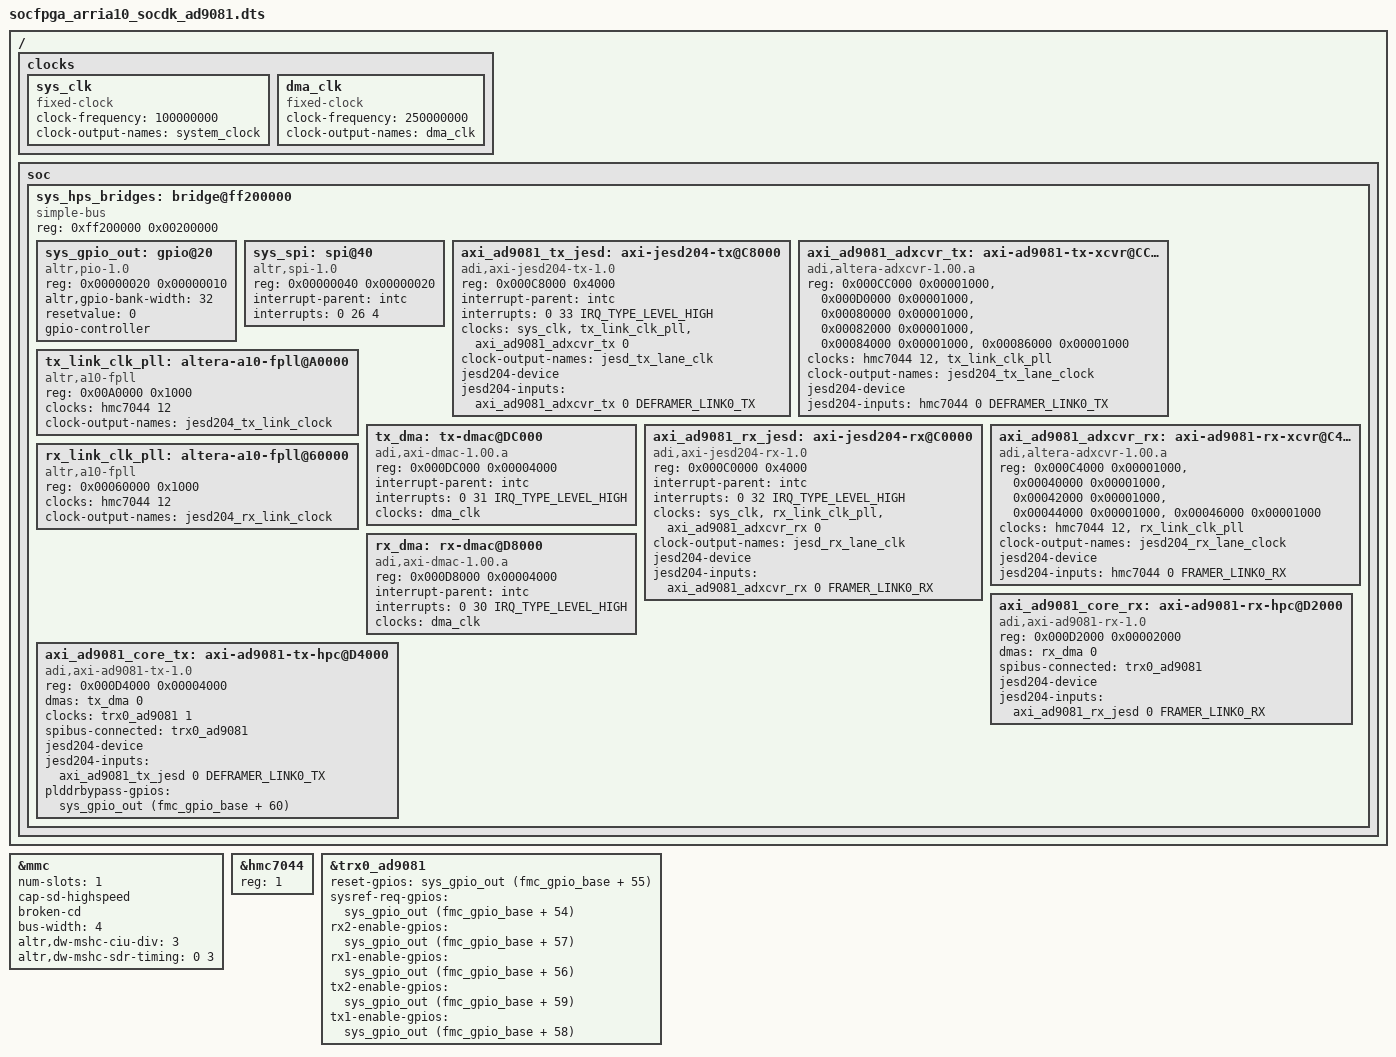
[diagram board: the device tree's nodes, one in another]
// SPDX-License-Identifier: GPL-2.0
/*
 * Analog Devices AD9081
 * https://wiki.analog.com/resources/eval/user-guides/ad9081_fmca_ebz
 * https://wiki.analog.com/resources/tools-software/linux-drivers/iio-mxfe/ad9081
 *
 * hdl_project: <ad9081_fmca_ebz/a10soc>
 * board_revision: <>
 *
 * Copyright (C) 2019 Analog Devices Inc.
 */
/dts-v1/;

#include "socfpga_arria10_socdk.dtsi"
#include <dt-bindings/interrupt-controller/irq.h>
#include <dt-bindings/iio/adc/adi,ad9081.h>
#include <dt-bindings/jesd204/adxcvr.h>

&mmc {
	status = "okay";
	num-slots = <1>;
	cap-sd-highspeed;
	broken-cd;
	bus-width = <4>;
	altr,dw-mshc-ciu-div = <3>;
	altr,dw-mshc-sdr-timing = <0 3>;
};

/ {
	clocks {
		sys_clk: sys_clk {
			#clock-cells = <0>;
			compatible = "fixed-clock";
			clock-frequency = <100000000>;
			clock-output-names = "system_clock";
		};

		dma_clk: dma_clk {
			#clock-cells = <0x0>;
			compatible = "fixed-clock";
			clock-frequency = <250000000>;
			clock-output-names = "dma_clk";
		};
	};

	soc {
		sys_hps_bridges: bridge@ff200000 {
			compatible = "simple-bus";
			reg = <0xff200000 0x00200000>;
			#address-cells = <1>;
			#size-cells = <1>;
			ranges = <0x00000000 0xff200000 0x00200000>;

			sys_gpio_out: gpio@20 {
				compatible = "altr,pio-1.0";
				reg = <0x00000020 0x00000010>;
				altr,gpio-bank-width = <32>;
				resetvalue = <0>;
				#gpio-cells = <2>;
				gpio-controller;
			};

			sys_spi: spi@40 {
				compatible = "altr,spi-1.0";
				reg = <0x00000040 0x00000020>;
				interrupt-parent = <&intc>;
				interrupts = <0 26 4>;
				#address-cells = <0x1>;
				#size-cells = <0x0>;
			};

			axi_ad9081_tx_jesd: axi-jesd204-tx@C8000 {
				compatible = "adi,axi-jesd204-tx-1.0";
				reg = <0x000C8000 0x4000>;

				interrupt-parent = <&intc>;
				interrupts = <0 33 IRQ_TYPE_LEVEL_HIGH>;

				clocks = <&sys_clk>, <&tx_link_clk_pll>, <&axi_ad9081_adxcvr_tx 0>;
				clock-names = "s_axi_aclk", "device_clk", "lane_clk";

				#clock-cells = <0>;
				clock-output-names = "jesd_tx_lane_clk";

				jesd204-device;
				#jesd204-cells = <2>;
				jesd204-inputs = <&axi_ad9081_adxcvr_tx 0 DEFRAMER_LINK0_TX>;
			};

			axi_ad9081_adxcvr_tx: axi-ad9081-tx-xcvr@CC000 {
				compatible = "adi,altera-adxcvr-1.00.a";
				reg = <0x000CC000 0x00001000>,
					<0x000D0000 0x00001000>,
					<0x00080000 0x00001000>,
					<0x00082000 0x00001000>,
					<0x00084000 0x00001000>,
					<0x00086000 0x00001000>;
				reg-names = "adxcvr", "atx-pll", "adxcfg-0", "adxcfg-1", "adxcfg-2", "adxcfg-3";

				clocks = <&hmc7044 12>, <&tx_link_clk_pll>;
				clock-names = "ref", "link";

				#clock-cells = <0>;
				clock-output-names = "jesd204_tx_lane_clock";

				jesd204-device;
				#jesd204-cells = <2>;
				jesd204-inputs =  <&hmc7044 0 DEFRAMER_LINK0_TX>;
			};

			tx_link_clk_pll: altera-a10-fpll@A0000 {
				compatible = "altr,a10-fpll";
				reg = <0x00A0000 0x1000>;
				clocks = <&hmc7044 12>;

				#clock-cells = <0>;
				clock-output-names = "jesd204_tx_link_clock";
			};

			tx_dma: tx-dmac@DC000 {
				compatible = "adi,axi-dmac-1.00.a";
				reg = <0x000DC000 0x00004000>;
				interrupt-parent = <&intc>;
				interrupts = <0 31 IRQ_TYPE_LEVEL_HIGH>;
				#dma-cells = <1>;
				clocks = <&dma_clk>;
			};

			axi_ad9081_rx_jesd: axi-jesd204-rx@C0000 {
				compatible = "adi,axi-jesd204-rx-1.0";
				reg = <0x000C0000 0x4000>;

				interrupt-parent = <&intc>;
				interrupts = <0 32 IRQ_TYPE_LEVEL_HIGH>;

				clocks = <&sys_clk>, <&rx_link_clk_pll>, <&axi_ad9081_adxcvr_rx 0>;
				clock-names = "s_axi_aclk", "device_clk", "lane_clk";

				#clock-cells = <0>;
				clock-output-names = "jesd_rx_lane_clk";

				jesd204-device;
				#jesd204-cells = <2>;
				jesd204-inputs = <&axi_ad9081_adxcvr_rx 0 FRAMER_LINK0_RX>;
			};

			axi_ad9081_adxcvr_rx: axi-ad9081-rx-xcvr@C4000 {
				compatible = "adi,altera-adxcvr-1.00.a";
				reg = <0x000C4000 0x00001000>,
					<0x00040000 0x00001000>,
					<0x00042000 0x00001000>,
					<0x00044000 0x00001000>,
					<0x00046000 0x00001000>;
				reg-names = "adxcvr", "adxcfg-0", "adxcfg-1", "adxcfg-2", "adxcfg-3";

				clocks = <&hmc7044 12>, <&rx_link_clk_pll>;
				clock-names = "ref", "link";

				#clock-cells = <0>;
				clock-output-names = "jesd204_rx_lane_clock";

				jesd204-device;
				#jesd204-cells = <2>;
				jesd204-inputs =  <&hmc7044 0 FRAMER_LINK0_RX>;
			};

			rx_link_clk_pll: altera-a10-fpll@60000 {
				compatible = "altr,a10-fpll";
				reg = <0x00060000 0x1000>;
				clocks = <&hmc7044 12>;

				#clock-cells = <0>;
				clock-output-names = "jesd204_rx_link_clock";
			};

			rx_dma: rx-dmac@D8000 {
				compatible = "adi,axi-dmac-1.00.a";
				reg = <0x000D8000 0x00004000>;
				interrupt-parent = <&intc>;
				interrupts = <0 30 IRQ_TYPE_LEVEL_HIGH>;
				#dma-cells = <1>;
				clocks = <&dma_clk>;
			};

			axi_ad9081_core_rx: axi-ad9081-rx-hpc@D2000 {
				compatible = "adi,axi-ad9081-rx-1.0";
				reg = <0x000D2000 0x00002000>;
				dmas = <&rx_dma 0>;
				dma-names = "rx";
				spibus-connected = <&trx0_ad9081>;

				jesd204-device;
				#jesd204-cells = <2>;
				jesd204-inputs = <&axi_ad9081_rx_jesd 0 FRAMER_LINK0_RX>;
			};

			axi_ad9081_core_tx: axi-ad9081-tx-hpc@D4000 {
				compatible = "adi,axi-ad9081-tx-1.0";
				reg = <0x000D4000 0x00004000>;
				dmas = <&tx_dma 0>;
				dma-names = "tx";
				clocks = <&trx0_ad9081 1>;
				clock-names = "sampl_clk";
				spibus-connected = <&trx0_ad9081>;
				
				jesd204-device;
				#jesd204-cells = <2>;
				jesd204-inputs = <&axi_ad9081_tx_jesd 0 DEFRAMER_LINK0_TX>;
			};
		};
	};
};

#define fmc_spi sys_spi
#define spi1 sys_spi

#include "adi-ad9081-fmc-ebz.dtsi"

&hmc7044 {
	reg = <1>;
};

#define fmc_gpio_base -32

&trx0_ad9081 {
	reset-gpios = <&sys_gpio_out (fmc_gpio_base + 55) 0>;
	sysref-req-gpios = <&sys_gpio_out (fmc_gpio_base + 54) 0>;
	rx2-enable-gpios = <&sys_gpio_out (fmc_gpio_base + 57) 0>;
	rx1-enable-gpios = <&sys_gpio_out (fmc_gpio_base + 56) 0>;
	tx2-enable-gpios = <&sys_gpio_out (fmc_gpio_base + 59) 0>;
	tx1-enable-gpios = <&sys_gpio_out (fmc_gpio_base + 58) 0>;
};

&axi_ad9081_core_tx {
	plddrbypass-gpios = <&sys_gpio_out (fmc_gpio_base + 60) 0>;
};
